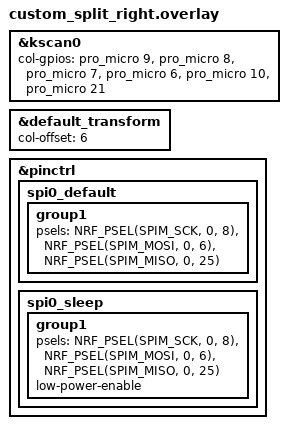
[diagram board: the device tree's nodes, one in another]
#include "custom_split.dtsi" // The shared dtsi file is included in the overlay

// Label of the kscan node in the dtsi
&kscan0 {
    col-gpios
        = <&pro_micro 9 (GPIO_ACTIVE_HIGH | GPIO_PULL_DOWN)>
        , <&pro_micro 8 (GPIO_ACTIVE_HIGH | GPIO_PULL_DOWN)>
        , <&pro_micro 7 (GPIO_ACTIVE_HIGH | GPIO_PULL_DOWN)>
        , <&pro_micro 6 (GPIO_ACTIVE_HIGH | GPIO_PULL_DOWN)>
        , <&pro_micro 10 (GPIO_ACTIVE_HIGH | GPIO_PULL_DOWN)>
        , <&pro_micro 21 (GPIO_ACTIVE_HIGH | GPIO_PULL_DOWN)>
        ;
};

&default_transform { // Offset of 6 because the left side has 6 columns
    col-offset = <6>;
};

&pinctrl {
    spi0_default: spi0_default {
        group1 {
            psels = <NRF_PSEL(SPIM_SCK, 0, 8)>,
                <NRF_PSEL(SPIM_MOSI, 0, 6)>,
                <NRF_PSEL(SPIM_MISO, 0, 25)>;
        };
    };
    spi0_sleep: spi0_sleep {
        group1 {
            psels = <NRF_PSEL(SPIM_SCK, 0, 8)>,
                <NRF_PSEL(SPIM_MOSI, 0, 6)>,
                <NRF_PSEL(SPIM_MISO, 0, 25)>;
            low-power-enable;
        };
    };
};
